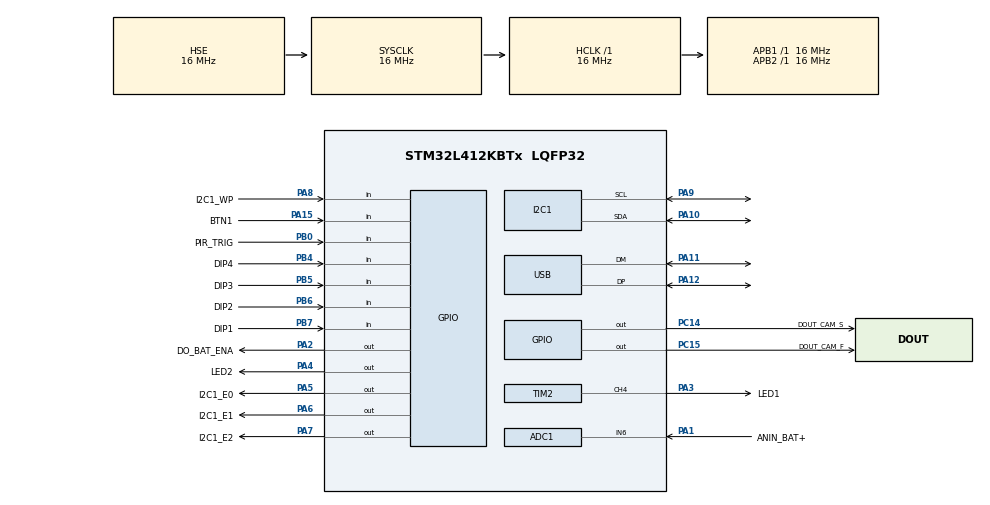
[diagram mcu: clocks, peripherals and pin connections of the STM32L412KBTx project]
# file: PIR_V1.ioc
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ADC1.Channel-0\#ChannelRegularConversion=ADC_CHANNEL_6
ADC1.NbrOfConversionFlag=1
ADC1.OffsetNumber-0\#ChannelRegularConversion=ADC_OFFSET_NONE
ADC1.Rank-0\#ChannelRegularConversion=1
ADC1.SamplingTime-0\#ChannelRegularConversion=ADC_SAMPLETIME_2CYCLES_5
ADC1.master=1
I2C1.Timing=0x00303D5B
Mcu.Family=STM32L4
Mcu.Name=STM32L412KBTx
Mcu.Package=LQFP32
NVIC.PriorityGroup=NVIC_PRIORITYGROUP_4
NVIC.USB_IRQn=true\:0\:0\:false\:false\:true\:false\:true\:true
PA0-CK_IN.Mode=HSE-External-Clock-Source-for-LittleOrca
PA0-CK_IN.Signal=RCC_CK_IN
PA1.GPIO_Label=ANIN_BAT+
PA1.Signal=ADCx_IN6
PA10.Mode=I2C
PA10.Signal=I2C1_SDA
PA11.Mode=Device
PA11.Signal=USB_DM
PA12.Mode=Device
PA12.Signal=USB_DP
PA13\ (JTMS/SWDIO).Mode=Trace_Asynchronous_SW
PA13\ (JTMS/SWDIO).Signal=SYS_JTMS-SWDIO
PA14\ (JTCK/SWCLK).Mode=Trace_Asynchronous_SW
PA14\ (JTCK/SWCLK).Signal=SYS_JTCK-SWCLK
PA15\ (JTDI).GPIO_Label=BTN1
PA15\ (JTDI).Signal=GPIO_Input
PA2.GPIO_Label=DO_BAT_ENA
PA2.Signal=GPIO_Output
PA3.GPIO_Label=LED1
PA3.Signal=S_TIM2_CH4
PA4.GPIO_Label=LED2
PA4.Signal=GPIO_Output
PA5.GPIO_Label=I2C1_E0
PA5.Signal=GPIO_Output
PA6.GPIO_Label=I2C1_E1
PA6.Signal=GPIO_Output
PA7.GPIO_Label=I2C1_E2
PA7.Signal=GPIO_Output
PA8.GPIO_Label=I2C1_WP
PA8.Signal=GPIO_Input
PA9.Mode=I2C
PA9.Signal=I2C1_SCL
PB0.GPIO_Label=PIR_TRIG
PB0.Signal=GPIO_Input
PB3\ (JTDO/TRACESWO).Mode=Trace_Asynchronous_SW
PB3\ (JTDO/TRACESWO).Signal=SYS_JTDO-SWO
PB4\ (NJTRST).GPIO_Label=DIP4
PB4\ (NJTRST).Signal=GPIO_Input
PB5.GPIO_Label=DIP3
PB5.Signal=GPIO_Input
PB6.GPIO_Label=DIP2
PB6.Signal=GPIO_Input
PB7.GPIO_Label=DIP1
PB7.Signal=GPIO_Input
PC14-OSC32_IN\ (PC14).GPIO_Label=DOUT_CAM_S
PC14-OSC32_IN\ (PC14).Signal=GPIO_Output
PC15-OSC32_OUT\ (PC15).GPIO_Label=DOUT_CAM_F
PC15-OSC32_OUT\ (PC15).Signal=GPIO_Output
ProjectManager.HeapSize=0x200
ProjectManager.StackSize=0x400
ProjectManager.TargetToolchain=STM32CubeIDE
RCC.ADCFreq_Value=16000000
RCC.AHBFreq_Value=16000000
RCC.APB1Freq_Value=16000000
RCC.APB1TimFreq_Value=16000000
RCC.APB2Freq_Value=16000000
RCC.APB2TimFreq_Value=16000000
RCC.CK48CLockSelection=RCC_USBCLKSOURCE_HSI48
RCC.CortexFreq_Value=16000000
RCC.HCLKFreq_Value=16000000
RCC.HSE_VALUE=16000000
RCC.HSI48_VALUE=48000000
RCC.HSI_VALUE=16000000
RCC.LSE_VALUE=32768
RCC.MSIClockRange=RCC_MSIRANGE_10
RCC.MSI_VALUE=32000000
RCC.PLLSourceVirtual=RCC_PLLSOURCE_HSE
RCC.SYSCLKFreq_VALUE=16000000
RCC.SYSCLKSource=RCC_SYSCLKSOURCE_HSE
RCC.USBFreq_Value=48000000
RCC.VCOOutputFreq_Value=128000000
SH.ADCx_IN6.0=ADC1_IN6,IN6-Single-Ended
SH.S_TIM2_CH4.0=TIM2_CH4,PWM Generation4 CH4
TIM2.Channel-PWM\ Generation4\ CH4=TIM_CHANNEL_4
USB_DEVICE.CLASS_NAME_FS=CDC
USB_DEVICE.VirtualMode=Cdc
USB_DEVICE.VirtualModeFS=Cdc_FS
VP_ADC1_TempSens_Input.Mode=IN-TempSens
VP_USB_DEVICE_VS_USB_DEVICE_CDC_FS.Mode=CDC_FS
board=custom

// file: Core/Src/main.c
/* USER CODE BEGIN Header */
/**
  ******************************************************************************
  * @file           : main.c
  * @brief          : Main program body
  ******************************************************************************
  * @attention
  *
  * Copyright (c) 2023 STMicroelectronics.
  * All rights reserved.
  *
  * This software is licensed under terms that can be found in the LICENSE file
  * in the root directory of this software component.
  * If no LICENSE file comes with this software, it is provided AS-IS.
  *
  ******************************************************************************
  */
/* USER CODE END Header */
#include "main.h"
#include "usb_device.h"

ADC_HandleTypeDef hadc1;

I2C_HandleTypeDef hi2c1;

TIM_HandleTypeDef htim2;

void SystemClock_Config(void);
static void MX_GPIO_Init(void);
static void MX_ADC1_Init(void);
static void MX_I2C1_Init(void);
static void MX_TIM2_Init(void);

int main(void)
{

  /* MCU Configuration--------------------------------------------------------*/

  /* Reset of all peripherals, Initializes the Flash interface and the Systick. */
  HAL_Init();

  /* Configure the system clock */
  SystemClock_Config();

  /* Initialize all configured peripherals */
  MX_GPIO_Init();
  MX_ADC1_Init();
  MX_I2C1_Init();
  MX_TIM2_Init();
  MX_USB_DEVICE_Init();

  /* Infinite loop */
  /* USER CODE BEGIN WHILE */
  while (1)
  {
	  // read battery voltage

	  // define interrupt

	  // read settings

	  // go to sleep

    /* USER CODE END WHILE */

  }
}

void SystemClock_Config(void)
{
  RCC_OscInitTypeDef RCC_OscInitStruct = {0};
  RCC_ClkInitTypeDef RCC_ClkInitStruct = {0};

  /** Configure the main internal regulator output voltage
  */
  if (HAL_PWREx_ControlVoltageScaling(PWR_REGULATOR_VOLTAGE_SCALE1) != HAL_OK)
  {
    Error_Handler();
  }

  /** Initializes the RCC Oscillators according to the specified parameters
  * in the RCC_OscInitTypeDef structure.
  */
  RCC_OscInitStruct.OscillatorType = RCC_OSCILLATORTYPE_HSI48|RCC_OSCILLATORTYPE_HSE;
  RCC_OscInitStruct.HSEState = RCC_HSE_BYPASS;
  RCC_OscInitStruct.HSI48State = RCC_HSI48_ON;
  RCC_OscInitStruct.PLL.PLLState = RCC_PLL_NONE;
  if (HAL_RCC_OscConfig(&RCC_OscInitStruct) != HAL_OK)
  {
    Error_Handler();
  }

  /** Initializes the CPU, AHB and APB buses clocks
  */
  RCC_ClkInitStruct.ClockType = RCC_CLOCKTYPE_HCLK|RCC_CLOCKTYPE_SYSCLK
                              |RCC_CLOCKTYPE_PCLK1|RCC_CLOCKTYPE_PCLK2;
  RCC_ClkInitStruct.SYSCLKSource = RCC_SYSCLKSOURCE_HSE;
  RCC_ClkInitStruct.AHBCLKDivider = RCC_SYSCLK_DIV1;
  RCC_ClkInitStruct.APB1CLKDivider = RCC_HCLK_DIV1;
  RCC_ClkInitStruct.APB2CLKDivider = RCC_HCLK_DIV1;

  if (HAL_RCC_ClockConfig(&RCC_ClkInitStruct, FLASH_LATENCY_0) != HAL_OK)
  {
    Error_Handler();
  }
}

static void MX_ADC1_Init(void)
{

  ADC_MultiModeTypeDef multimode = {0};
  ADC_ChannelConfTypeDef sConfig = {0};

  /** Common config
  */
  hadc1.Instance = ADC1;
  hadc1.Init.ClockPrescaler = ADC_CLOCK_ASYNC_DIV1;
  hadc1.Init.Resolution = ADC_RESOLUTION_12B;
  hadc1.Init.DataAlign = ADC_DATAALIGN_RIGHT;
  hadc1.Init.ScanConvMode = ADC_SCAN_DISABLE;
  hadc1.Init.EOCSelection = ADC_EOC_SINGLE_CONV;
  hadc1.Init.LowPowerAutoWait = DISABLE;
  hadc1.Init.ContinuousConvMode = DISABLE;
  hadc1.Init.NbrOfConversion = 1;
  hadc1.Init.DiscontinuousConvMode = DISABLE;
  hadc1.Init.ExternalTrigConv = ADC_SOFTWARE_START;
  hadc1.Init.ExternalTrigConvEdge = ADC_EXTERNALTRIGCONVEDGE_NONE;
  hadc1.Init.DMAContinuousRequests = DISABLE;
  hadc1.Init.Overrun = ADC_OVR_DATA_PRESERVED;
  hadc1.Init.OversamplingMode = DISABLE;
  if (HAL_ADC_Init(&hadc1) != HAL_OK)
  {
    Error_Handler();
  }

  /** Configure the ADC multi-mode
  */
  multimode.Mode = ADC_MODE_INDEPENDENT;
  if (HAL_ADCEx_MultiModeConfigChannel(&hadc1, &multimode) != HAL_OK)
  {
    Error_Handler();
  }

  /** Configure Regular Channel
  */
  sConfig.Channel = ADC_CHANNEL_6;
  sConfig.Rank = ADC_REGULAR_RANK_1;
  sConfig.SamplingTime = ADC_SAMPLETIME_2CYCLES_5;
  sConfig.SingleDiff = ADC_SINGLE_ENDED;
  sConfig.OffsetNumber = ADC_OFFSET_NONE;
  sConfig.Offset = 0;
  if (HAL_ADC_ConfigChannel(&hadc1, &sConfig) != HAL_OK)
  {
    Error_Handler();
  }

}

static void MX_I2C1_Init(void)
{

  hi2c1.Instance = I2C1;
  hi2c1.Init.Timing = 0x00303D5B;
  hi2c1.Init.OwnAddress1 = 0;
  hi2c1.Init.AddressingMode = I2C_ADDRESSINGMODE_7BIT;
  hi2c1.Init.DualAddressMode = I2C_DUALADDRESS_DISABLE;
  hi2c1.Init.OwnAddress2 = 0;
  hi2c1.Init.OwnAddress2Masks = I2C_OA2_NOMASK;
  hi2c1.Init.GeneralCallMode = I2C_GENERALCALL_DISABLE;
  hi2c1.Init.NoStretchMode = I2C_NOSTRETCH_DISABLE;
  if (HAL_I2C_Init(&hi2c1) != HAL_OK)
  {
    Error_Handler();
  }

  /** Configure Analogue filter
  */
  if (HAL_I2CEx_ConfigAnalogFilter(&hi2c1, I2C_ANALOGFILTER_ENABLE) != HAL_OK)
  {
    Error_Handler();
  }

  /** Configure Digital filter
  */
  if (HAL_I2CEx_ConfigDigitalFilter(&hi2c1, 0) != HAL_OK)
  {
    Error_Handler();
  }

}

static void MX_TIM2_Init(void)
{

  TIM_MasterConfigTypeDef sMasterConfig = {0};
  TIM_OC_InitTypeDef sConfigOC = {0};

  htim2.Instance = TIM2;
  htim2.Init.Prescaler = 0;
  htim2.Init.CounterMode = TIM_COUNTERMODE_UP;
  htim2.Init.Period = 4294967295;
  htim2.Init.ClockDivision = TIM_CLOCKDIVISION_DIV1;
  htim2.Init.AutoReloadPreload = TIM_AUTORELOAD_PRELOAD_DISABLE;
  if (HAL_TIM_PWM_Init(&htim2) != HAL_OK)
  {
    Error_Handler();
  }
  sMasterConfig.MasterOutputTrigger = TIM_TRGO_RESET;
  sMasterConfig.MasterSlaveMode = TIM_MASTERSLAVEMODE_DISABLE;
  if (HAL_TIMEx_MasterConfigSynchronization(&htim2, &sMasterConfig) != HAL_OK)
  {
    Error_Handler();
  }
  sConfigOC.OCMode = TIM_OCMODE_PWM1;
  sConfigOC.Pulse = 0;
  sConfigOC.OCPolarity = TIM_OCPOLARITY_HIGH;
  sConfigOC.OCFastMode = TIM_OCFAST_DISABLE;
  if (HAL_TIM_PWM_ConfigChannel(&htim2, &sConfigOC, TIM_CHANNEL_4) != HAL_OK)
  {
    Error_Handler();
  }
  HAL_TIM_MspPostInit(&htim2);

}

static void MX_GPIO_Init(void)
{
  GPIO_InitTypeDef GPIO_InitStruct = {0};

  /* GPIO Ports Clock Enable */
  __HAL_RCC_GPIOC_CLK_ENABLE();
  __HAL_RCC_GPIOA_CLK_ENABLE();
  __HAL_RCC_GPIOB_CLK_ENABLE();

  /*Configure GPIO pin Output Level */
  HAL_GPIO_WritePin(GPIOC, DOUT_CAM_S_Pin|DOUT_CAM_F_Pin, GPIO_PIN_RESET);

  /*Configure GPIO pin Output Level */
  HAL_GPIO_WritePin(GPIOA, DO_BAT_ENA_Pin|LED2_Pin|I2C1_E0_Pin|I2C1_E1_Pin
                          |I2C1_E2_Pin, GPIO_PIN_RESET);

  /*Configure GPIO pins : DOUT_CAM_S_Pin DOUT_CAM_F_Pin */
  GPIO_InitStruct.Pin = DOUT_CAM_S_Pin|DOUT_CAM_F_Pin;
  GPIO_InitStruct.Mode = GPIO_MODE_OUTPUT_PP;
  GPIO_InitStruct.Pull = GPIO_NOPULL;
  GPIO_InitStruct.Speed = GPIO_SPEED_FREQ_LOW;
  HAL_GPIO_Init(GPIOC, &GPIO_InitStruct);

  /*Configure GPIO pins : DO_BAT_ENA_Pin LED2_Pin I2C1_E0_Pin I2C1_E1_Pin
                           I2C1_E2_Pin */
  GPIO_InitStruct.Pin = DO_BAT_ENA_Pin|LED2_Pin|I2C1_E0_Pin|I2C1_E1_Pin
                          |I2C1_E2_Pin;
  GPIO_InitStruct.Mode = GPIO_MODE_OUTPUT_PP;
  GPIO_InitStruct.Pull = GPIO_NOPULL;
  GPIO_InitStruct.Speed = GPIO_SPEED_FREQ_LOW;
  HAL_GPIO_Init(GPIOA, &GPIO_InitStruct);

  /*Configure GPIO pins : PIR_TRIG_Pin DIP4_Pin DIP3_Pin DIP2_Pin
                           DIP1_Pin */
  GPIO_InitStruct.Pin = PIR_TRIG_Pin|DIP4_Pin|DIP3_Pin|DIP2_Pin
                          |DIP1_Pin;
  GPIO_InitStruct.Mode = GPIO_MODE_INPUT;
  GPIO_InitStruct.Pull = GPIO_NOPULL;
  HAL_GPIO_Init(GPIOB, &GPIO_InitStruct);

  /*Configure GPIO pins : I2C1_WP_Pin BTN1_Pin */
  GPIO_InitStruct.Pin = I2C1_WP_Pin|BTN1_Pin;
  GPIO_InitStruct.Mode = GPIO_MODE_INPUT;
  GPIO_InitStruct.Pull = GPIO_NOPULL;
  HAL_GPIO_Init(GPIOA, &GPIO_InitStruct);

}

void Error_Handler(void)
{
  __disable_irq();
  while (1)
  {
  }
}
